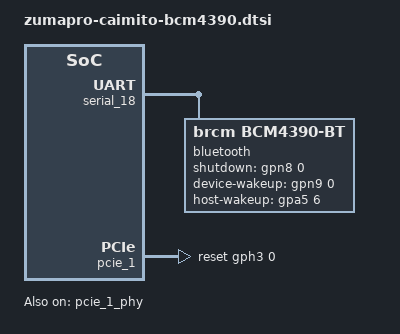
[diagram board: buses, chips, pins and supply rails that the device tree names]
// SPDX-License-Identifier: GPL-2.0-only
/*
 * Device tree for the boards that carry the Broadcom BCM4390 combo chip:
 * caiman, komodo, tokay and comet (tegu uses a different part).
 *
 * Copyright 2025 Trijal Saha - <trijalsaha2012@gmail.com>
 */

#include <dt-bindings/gpio/gpio.h>

/*
 * Bluetooth HCI on UART18.  The BCM4390's BT controller talks H4 on this port,
 * but the AOC coprocessor can own it too (APM USI1 is reachable from both), and
 * the vendor stack prefers the AOC path -- its HAL config asks for
 * SerialAocUartPort first and falls back to this UART second.  With the AOC's
 * Bluetooth firmware not running (do not load the AOC driver), the port is the
 * AP's and the ordinary mainline hci_uart/hci_bcm stack drives the controller.
 */
&serial_18 {
	bluetooth {
		compatible = "brcm,bcm4390-bt";
		shutdown-gpios = <&gpn8 0 GPIO_ACTIVE_HIGH>;	  /* BT_REG_ON */
		device-wakeup-gpios = <&gpn9 0 GPIO_ACTIVE_HIGH>; /* BT_DEV_WAKE */
		host-wakeup-gpios = <&gpa5 6 GPIO_ACTIVE_HIGH>;	  /* BT_HOST_WAKE */
		max-speed = <115200>;
	};
};

/* PCIe channel 1 (HSI2) connects to the Broadcom BCM4390 Wi-Fi. */
&pcie_1_phy {
	status = "okay";
};

&pcie_1 {
	pinctrl-0 = <&pcie1_clkreq &pcie1_perst>;
	pinctrl-names = "default";
	reset-gpios = <&gph3 0 GPIO_ACTIVE_HIGH>;	/* PERST */
	wlan-reg-on-gpios = <&gph3 4 GPIO_ACTIVE_HIGH>;	/* WLAN_EN */
	/* Out-of-band wake lines for the BCM4390 endpoint: WL_HOST_WAKE is the
	 * device-to-host interrupt (the dongle has no usable in-band D2H
	 * doorbell), WL_DEV_WAKE lets the host wake the dongle from deep sleep.
	 */
	host-wake-gpios = <&gpa5 3 GPIO_ACTIVE_HIGH>;	/* WL_HOST_WAKE */
	device-wake-gpios = <&gph3 5 GPIO_ACTIVE_HIGH>;	/* WL_DEV_WAKE */
	status = "okay";
};

/*
 * Standalone platform node the Broadcom bcmdhd (dhd) driver looks up by
 * compatible string (of_find_compatible_node) to obtain the WLAN GPIOs and the
 * PCIe channel index. It is NOT the PCIe endpoint (that binds by PCI id under
 * &pcie_1). WLAN_EN is owned/driven by pci-exynos for link enumeration; dhd
 * re-requests the same pin and tolerates the request failing (it reads the pin
 * already-high and skips re-driving). Only used when the bcmdhd driver replaces
 * brcmfmac; harmless otherwise.
 */
/ {
	bcmdhd_wlan: wlan {
		compatible = "android,bcmdhd_wlan";
		wl_reg_on = <&gph3 4 GPIO_ACTIVE_HIGH>;		/* WLAN_EN (shared w/ pci-exynos) */
		wl_host_wake = <&gpa5 3 GPIO_ACTIVE_HIGH>;	/* WL_HOST_WAKE (OOB D2H) */
		ch-num = <1>;					/* PCIe HSI2 channel */
		status = "okay";
	};

	/*
	 * Bluetooth half of the same BCM4390.  Unlike Wi-Fi (PCIe, AP-direct)
	 * the BT controller's HCI UART lands on the AOC, not the AP: the AOC
	 * firmware carries platform_bt_uart_driver.cc / uart_[UART_MAP_BT] and
	 * a Pigweed "btproxy" that relays H4 to the host, so the transport is
	 * hci_aoc over the AOC's chre_bt_offload_* ring services and the AP
	 * owns only the power/wake pins.  Probed on device: an AP-UART HCI
	 * sweep (6 bauds x flow control, verified pinmux) was silent, the chip
	 * exposes no second PCIe function, and the AOC's 94-service table has
	 * no com.google.bt -- the offload rings are the only BT pipe.
	 */
	bluetooth: bluetooth {
		compatible = "google,aoc-bluetooth";
		aoc = <&aoc>;
		shutdown-gpios = <&gpn8 0 GPIO_ACTIVE_HIGH>;	  /* BT_REG_ON */
		device-wakeup-gpios = <&gpn9 0 GPIO_ACTIVE_HIGH>; /* BT_DEV_WAKE */
		/*
		 * Mutually exclusive with the serdev node under &serial_18
		 * above: both claim BT_REG_ON, so enabling both makes whichever
		 * probes second fail with -EBUSY.  The UART path is the one
		 * built out of upstream drivers, so it is the default; enable
		 * this instead only when driving Bluetooth through the AOC's
		 * chre_bt_offload rings (which additionally needs the AOC's
		 * framed ApTxHdr/AocTxHdr transport, not raw H4).
		 */
		status = "disabled";
	};
};
